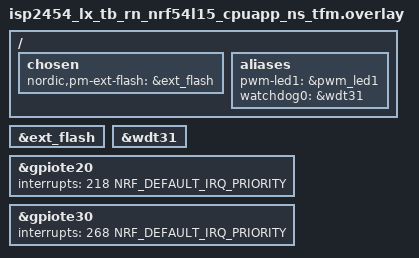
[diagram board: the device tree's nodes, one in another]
/*
 * Copyright (c) 2026 Nordic Semiconductor ASA
 *
 * SPDX-License-Identifier: LicenseRef-Nordic-5-Clause
 */

#include "isp2454_matter_tfm_base_partitions.dtsi"
#include "isp2454_matter_tfm_application_partitions.dtsi"

/ {
	chosen {
		nordic,pm-ext-flash = &ext_flash;
	};

	aliases {
		/* PWM LED used as the light: pwm_led1 (LED 1, P1.10, pwm20)
		 * is already defined by the board.
		 */
		pwm-led1 = &pwm_led1;

		/* Use watchdog wdt31 as the application watchdog */
		watchdog0 = &wdt31;
	};
};

&ext_flash {
	status = "okay";
};

&wdt31 {
	status = "okay";
};

/* Change IRQ ids to handle button interrupts.
 * The default values for nRF54L15 are 219 and 269,
 * but with TF-M they are reserved for the secure domain
 * (218 and 268 are reserved for the non-secure domain).
 */
&gpiote20 {
	interrupts = <218 NRF_DEFAULT_IRQ_PRIORITY>;
};

&gpiote30 {
	interrupts = <268 NRF_DEFAULT_IRQ_PRIORITY>;
};
